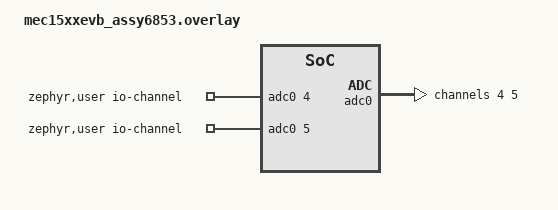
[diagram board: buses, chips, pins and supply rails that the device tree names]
/*
 * SPDX-License-Identifier: Apache-2.0
 *
 * Copyright (c) Benjamin Björnsson <benjamin.bjornsson@gmail.com>
 */

#include <zephyr/dt-bindings/adc/adc.h>

/ {
	zephyr,user {
		io-channels = <&adc0 4>, <&adc0 5>;
	};
};

&adc0 {
	#address-cells = <1>;
	#size-cells = <0>;

	channel@4 {
		reg = <4>;
		zephyr,gain = "ADC_GAIN_1";
		zephyr,reference = "ADC_REF_INTERNAL";
		zephyr,acquisition-time = <ADC_ACQ_TIME_DEFAULT>;
		zephyr,resolution = <12>;
	};

	channel@5 {
		reg = <5>;
		zephyr,gain = "ADC_GAIN_1";
		zephyr,reference = "ADC_REF_INTERNAL";
		zephyr,acquisition-time = <ADC_ACQ_TIME_DEFAULT>;
		zephyr,resolution = <12>;
	};
};
